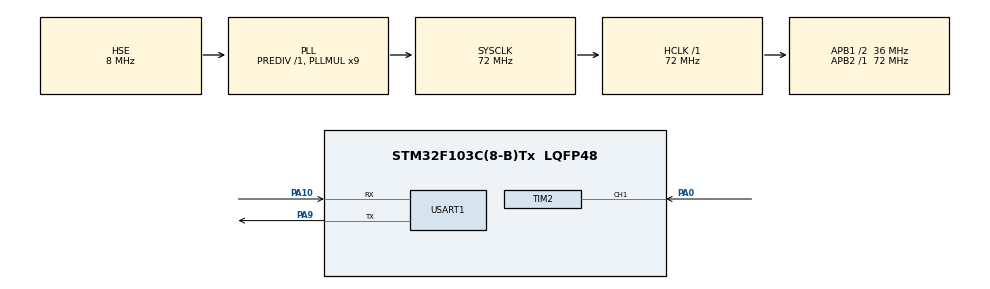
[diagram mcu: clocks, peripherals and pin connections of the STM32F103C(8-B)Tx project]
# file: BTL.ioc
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Mcu.Family=STM32F1
Mcu.Name=STM32F103C(8-B)Tx
Mcu.Package=LQFP48
NVIC.PriorityGroup=NVIC_PRIORITYGROUP_4
NVIC.TIM2_IRQn=true\:0\:0\:false\:false\:true\:true\:true\:true
PA0-WKUP.Signal=S_TIM2_CH1_ETR
PA10.Mode=Asynchronous
PA10.Signal=USART1_RX
PA13.Mode=Serial_Wire
PA13.Signal=SYS_JTMS-SWDIO
PA14.Mode=Serial_Wire
PA14.Signal=SYS_JTCK-SWCLK
PA9.Mode=Asynchronous
PA9.Signal=USART1_TX
PD0-OSC_IN.Mode=HSE-External-Oscillator
PD0-OSC_IN.Signal=RCC_OSC_IN
PD1-OSC_OUT.Mode=HSE-External-Oscillator
PD1-OSC_OUT.Signal=RCC_OSC_OUT
ProjectManager.HeapSize=0x200
ProjectManager.StackSize=0x400
ProjectManager.TargetToolchain=STM32CubeIDE
RCC.AHBFreq_Value=72000000
RCC.APB1CLKDivider=RCC_HCLK_DIV2
RCC.APB1Freq_Value=36000000
RCC.APB1TimFreq_Value=72000000
RCC.APB2Freq_Value=72000000
RCC.APB2TimFreq_Value=72000000
RCC.HCLKFreq_Value=72000000
RCC.PLLMUL=RCC_PLL_MUL9
RCC.PLLSourceVirtual=RCC_PLLSOURCE_HSE
RCC.SYSCLKFreq_VALUE=72000000
RCC.SYSCLKSource=RCC_SYSCLKSOURCE_PLLCLK
RCC.USBFreq_Value=72000000
SH.S_TIM2_CH1_ETR.0=TIM2_CH1,Input_Capture1_from_TI1
TIM2.Channel-Input_Capture1_from_TI1=TIM_CHANNEL_1
TIM2.Prescaler=71
USART1.VirtualMode=VM_ASYNC
VP_TIM2_VS_ClockSourceINT.Mode=Internal
board=custom

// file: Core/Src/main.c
/* USER CODE BEGIN Header */
/**
  ******************************************************************************
  * @file           : main.c
  * @brief          : Main program body
  ******************************************************************************
  * @attention
  *
  * Copyright (c) 2026 STMicroelectronics.
  * All rights reserved.
  *
  * This software is licensed under terms that can be found in the LICENSE file
  * in the root directory of this software component.
  * If no LICENSE file comes with this software, it is provided AS-IS.
  *
  ******************************************************************************
  */
/* USER CODE END Header */
#include "main.h"

/* USER CODE BEGIN Includes */
#include <stdio.h>
#include <string.h>
/* USER CODE END Includes */

/* USER CODE BEGIN PD */
#define UART_TX_INTERVAL_MS  500  // Khoảng thời gian gửi UART (ms)
/* USER CODE END PD */

TIM_HandleTypeDef htim2;

UART_HandleTypeDef huart1;

/* USER CODE BEGIN PV */
uint32_t IC_Val1 = 0;
uint32_t IC_Val2 = 0;
uint32_t Difference = 0;
uint8_t Is_First_Captured = 0;

float period_us = 0;
float temperature = 0;

#define FILTER_WINDOW 21
float temp_buffer[FILTER_WINDOW];
uint8_t temp_index = 0;
uint8_t is_buffer_filled = 0;

/* USART1 Transmit */
char uart_tx_buf[64];
uint32_t last_uart_tick = 0;
/* USER CODE END PV */

void SystemClock_Config(void);
static void MX_GPIO_Init(void);
static void MX_TIM2_Init(void);
static void MX_USART1_UART_Init(void);

/* USER CODE BEGIN 0 */
void HAL_TIM_IC_CaptureCallback(TIM_HandleTypeDef *htim)
{
  if (htim->Channel == HAL_TIM_ACTIVE_CHANNEL_1)
  {
    if (Is_First_Captured == 0)
    {
      IC_Val1 = HAL_TIM_ReadCapturedValue(htim, TIM_CHANNEL_1);
      Is_First_Captured = 1;
    }
    else if (Is_First_Captured == 1)
    {
      IC_Val2 = HAL_TIM_ReadCapturedValue(htim, TIM_CHANNEL_1);

      if (IC_Val2 > IC_Val1)
      {
        Difference = IC_Val2 - IC_Val1;
      }
      else if (IC_Val1 > IC_Val2)
      {
        Difference = (0xFFFF - IC_Val1) + IC_Val2 + 1;
      }

      period_us = (float)Difference;
      Is_First_Captured = 0;
    }
  }
}

// Hàm lọc chống nhiễu xung và làm mượt hạng nặng
float Stable_Filter(float new_value) {
    // 1. Nạp giá trị mới vào bộ đệm xoay vòng
    temp_buffer[temp_index] = new_value;
    temp_index++;
    if (temp_index >= FILTER_WINDOW) {
        temp_index = 0;
        is_buffer_filled = 1;
    }

    if (is_buffer_filled == 0) return new_value;

    // 2. Tạo mảng copy để sắp xếp
    float sort_buffer[FILTER_WINDOW];
    for (int i = 0; i < FILTER_WINDOW; i++) {
        sort_buffer[i] = temp_buffer[i];
    }

    // 3. Sắp xếp nổi bọt (Bubble Sort)
    for (int i = 0; i < FILTER_WINDOW - 1; i++) {
        for (int j = 0; j < FILTER_WINDOW - i - 1; j++) {
            if (sort_buffer[j] > sort_buffer[j+1]) {
                float temp = sort_buffer[j];
                sort_buffer[j] = sort_buffer[j+1];
                sort_buffer[j+1] = temp;
            }
        }
    }

    // 4. Lọc trung vị: Lấy phần tử ở chính giữa mảng 101 phần tử
    float median_value = sort_buffer[FILTER_WINDOW / 2];

    // 5. Lọc mượt EMA siêu chậm
    static float final_temp = 0;
    static uint8_t first_run = 1;

    if (first_run == 1) {
        final_temp = median_value;
        first_run = 0;
    } else {
        // Cập nhật 1% giá trị mới, giữ 99% giá trị cũ
        final_temp = final_temp + 0.1f * (median_value - final_temp);
    }

    return final_temp;
}
/* USER CODE END 0 */

int main(void)
{

  /* MCU Configuration--------------------------------------------------------*/

  /* Reset of all peripherals, Initializes the Flash interface and the Systick. */
  HAL_Init();

  /* Configure the system clock */
  SystemClock_Config();

  /* Initialize all configured peripherals */
  MX_GPIO_Init();
  MX_TIM2_Init();
  MX_USART1_UART_Init();
  /* USER CODE BEGIN 2 */
  HAL_TIM_IC_Start_IT(&htim2, TIM_CHANNEL_1);
  last_uart_tick = HAL_GetTick();
  /* USER CODE END 2 */

  /* Infinite loop */
  while (1)
  {

    /* USER CODE BEGIN 3 */
      if (period_us > 0)
      {
        // 1. Tính toán nhiệt độ thô từ chu kỳ đo được
        float tempK = 1.0f / (0.003354f - (period_us / 5569417.0f));
        float temperature_raw = tempK - 273.15f;

        // 2. Đưa giá trị thô qua bộ lọc trung vị 101 mẫu + EMA
        float filtered_temp = Stable_Filter(temperature_raw);

        // 3. Áp dụng phương trình hiệu chuẩn tuyến tính
        temperature = (1.104f * filtered_temp) - 1.7f;
      }

      // ---- USART1: Truyền nhiệt độ về PC mỗi 500ms ----
      if ((HAL_GetTick() - last_uart_tick) >= UART_TX_INTERVAL_MS)
      {
        last_uart_tick = HAL_GetTick();

        // Chuyển nhiệt độ float thành chuỗi dạng "TEMP:xx.xx\r\n"
        int temp_int  = (int)temperature;
        int temp_frac = (int)((temperature - (float)temp_int) * 100);
        if (temp_frac < 0) temp_frac = -temp_frac;

        sprintf(uart_tx_buf, "TEMP:%d.%02d\r\n", temp_int, temp_frac);
        HAL_UART_Transmit(&huart1, (uint8_t *)uart_tx_buf, strlen(uart_tx_buf), 100);
      }

      HAL_Delay(10); // Lấy mẫu liên tục với tốc độ cao (10ms)
  }
  /* USER CODE END 3 */
}

void SystemClock_Config(void)
{
  RCC_OscInitTypeDef RCC_OscInitStruct = {0};
  RCC_ClkInitTypeDef RCC_ClkInitStruct = {0};

  /** Initializes the RCC Oscillators according to the specified parameters
  * in the RCC_OscInitTypeDef structure.
  */
  RCC_OscInitStruct.OscillatorType = RCC_OSCILLATORTYPE_HSE;
  RCC_OscInitStruct.HSEState = RCC_HSE_ON;
  RCC_OscInitStruct.HSEPredivValue = RCC_HSE_PREDIV_DIV1;
  RCC_OscInitStruct.HSIState = RCC_HSI_ON;
  RCC_OscInitStruct.PLL.PLLState = RCC_PLL_ON;
  RCC_OscInitStruct.PLL.PLLSource = RCC_PLLSOURCE_HSE;
  RCC_OscInitStruct.PLL.PLLMUL = RCC_PLL_MUL9;
  if (HAL_RCC_OscConfig(&RCC_OscInitStruct) != HAL_OK)
  {
    Error_Handler();
  }

  /** Initializes the CPU, AHB and APB buses clocks
  */
  RCC_ClkInitStruct.ClockType = RCC_CLOCKTYPE_HCLK|RCC_CLOCKTYPE_SYSCLK
                              |RCC_CLOCKTYPE_PCLK1|RCC_CLOCKTYPE_PCLK2;
  RCC_ClkInitStruct.SYSCLKSource = RCC_SYSCLKSOURCE_PLLCLK;
  RCC_ClkInitStruct.AHBCLKDivider = RCC_SYSCLK_DIV1;
  RCC_ClkInitStruct.APB1CLKDivider = RCC_HCLK_DIV2;
  RCC_ClkInitStruct.APB2CLKDivider = RCC_HCLK_DIV1;

  if (HAL_RCC_ClockConfig(&RCC_ClkInitStruct, FLASH_LATENCY_2) != HAL_OK)
  {
    Error_Handler();
  }
}

static void MX_TIM2_Init(void)
{

  TIM_ClockConfigTypeDef sClockSourceConfig = {0};
  TIM_MasterConfigTypeDef sMasterConfig = {0};
  TIM_IC_InitTypeDef sConfigIC = {0};

  htim2.Instance = TIM2;
  htim2.Init.Prescaler = 71;
  htim2.Init.CounterMode = TIM_COUNTERMODE_UP;
  htim2.Init.Period = 65535;
  htim2.Init.ClockDivision = TIM_CLOCKDIVISION_DIV1;
  htim2.Init.AutoReloadPreload = TIM_AUTORELOAD_PRELOAD_DISABLE;
  if (HAL_TIM_Base_Init(&htim2) != HAL_OK)
  {
    Error_Handler();
  }
  sClockSourceConfig.ClockSource = TIM_CLOCKSOURCE_INTERNAL;
  if (HAL_TIM_ConfigClockSource(&htim2, &sClockSourceConfig) != HAL_OK)
  {
    Error_Handler();
  }
  if (HAL_TIM_IC_Init(&htim2) != HAL_OK)
  {
    Error_Handler();
  }
  sMasterConfig.MasterOutputTrigger = TIM_TRGO_RESET;
  sMasterConfig.MasterSlaveMode = TIM_MASTERSLAVEMODE_DISABLE;
  if (HAL_TIMEx_MasterConfigSynchronization(&htim2, &sMasterConfig) != HAL_OK)
  {
    Error_Handler();
  }
  sConfigIC.ICPolarity = TIM_INPUTCHANNELPOLARITY_RISING;
  sConfigIC.ICSelection = TIM_ICSELECTION_DIRECTTI;
  sConfigIC.ICPrescaler = TIM_ICPSC_DIV1;
  sConfigIC.ICFilter = 0;
  if (HAL_TIM_IC_ConfigChannel(&htim2, &sConfigIC, TIM_CHANNEL_1) != HAL_OK)
  {
    Error_Handler();
  }

}

static void MX_USART1_UART_Init(void)
{

  huart1.Instance = USART1;
  huart1.Init.BaudRate = 115200;
  huart1.Init.WordLength = UART_WORDLENGTH_8B;
  huart1.Init.StopBits = UART_STOPBITS_1;
  huart1.Init.Parity = UART_PARITY_NONE;
  huart1.Init.Mode = UART_MODE_TX_RX;
  huart1.Init.HwFlowCtl = UART_HWCONTROL_NONE;
  huart1.Init.OverSampling = UART_OVERSAMPLING_16;
  if (HAL_UART_Init(&huart1) != HAL_OK)
  {
    Error_Handler();
  }

}

static void MX_GPIO_Init(void)
{

  /* GPIO Ports Clock Enable */
  __HAL_RCC_GPIOD_CLK_ENABLE();
  __HAL_RCC_GPIOA_CLK_ENABLE();

}

void Error_Handler(void)
{
  __disable_irq();
  while (1)
  {
  }
}
